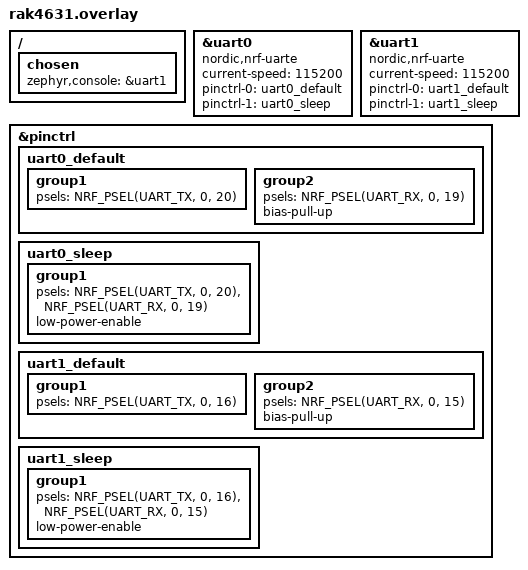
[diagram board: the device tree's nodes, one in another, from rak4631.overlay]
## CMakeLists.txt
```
cmake_minimum_required(VERSION 3.20.0)
find_package(Zephyr REQUIRED HINTS $ENV{ZEPHYR_BASE})
project(system_tower)
target_sources(app PRIVATE src/main.c)
```

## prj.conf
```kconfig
CONFIG_GPIO=y
CONFIG_SERIAL=y
CONFIG_CONSOLE=y
CONFIG_UART_CONSOLE=y
CONFIG_PRINTK=y
CONFIG_I2C=y

# LoRa (SX1262)
CONFIG_LORA=y
CONFIG_SPI=y

CONFIG_MAIN_STACK_SIZE=4096
CONFIG_SYSTEM_WORKQUEUE_STACK_SIZE=2048
```

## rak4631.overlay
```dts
/*
 * System Test - Tower
 * Console (debug): uart0 TX=P0.20, RX=P0.19 (115200) - RS485 경로
 * UART1: TX=P0.16, RX=P0.15 (115200) - debug/monitor 출력
 */

/ {
	chosen {
		zephyr,console = &uart1;
	};
};

&uart0 {
	compatible = "nordic,nrf-uarte";
	status = "okay";
	current-speed = <115200>;
	pinctrl-0 = <&uart0_default>;
	pinctrl-1 = <&uart0_sleep>;
	pinctrl-names = "default", "sleep";
};

&uart1 {
	compatible = "nordic,nrf-uarte";
	status = "okay";
	current-speed = <115200>;
	pinctrl-0 = <&uart1_default>;
	pinctrl-1 = <&uart1_sleep>;
	pinctrl-names = "default", "sleep";
};

&pinctrl {
	uart0_default: uart0_default {
		group1 {
			psels = <NRF_PSEL(UART_TX, 0, 20)>;
		};
		group2 {
			psels = <NRF_PSEL(UART_RX, 0, 19)>;
			bias-pull-up;
		};
	};

	uart0_sleep: uart0_sleep {
		group1 {
			psels = <NRF_PSEL(UART_TX, 0, 20)>,
				<NRF_PSEL(UART_RX, 0, 19)>;
			low-power-enable;
		};
	};

	uart1_default: uart1_default {
		group1 {
			psels = <NRF_PSEL(UART_TX, 0, 16)>;
		};
		group2 {
			psels = <NRF_PSEL(UART_RX, 0, 15)>;
			bias-pull-up;
		};
	};

	uart1_sleep: uart1_sleep {
		group1 {
			psels = <NRF_PSEL(UART_TX, 0, 16)>,
				<NRF_PSEL(UART_RX, 0, 15)>;
			low-power-enable;
		};
	};
};
```

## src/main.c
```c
/*
 * System Test - Tower (TX → RX loopback)
 *
 * 동작 (단일 스레드, 순차 처리):
 *   1. LoRa TX: 카운트 메시지 송신
 *   2. LoRa RX: Link에서 loopback된 메시지 수신 대기 (5초 timeout)
 *   3. 수신 결과를 uart1 (debug)과 RS485 (uart0)로 출력
 *   4. 반복
 *
 * RS485: MCP23017 → TMUX1574 MUX 활성화 후 uart0 사용
 * LoRa:  922.1 MHz, SF9, BW125, CR4/6
 */

#include <zephyr/kernel.h>
#include <zephyr/device.h>
#include <zephyr/drivers/gpio.h>
#include <zephyr/drivers/i2c.h>
#include <zephyr/drivers/uart.h>
#include <zephyr/drivers/lora.h>
#include <string.h>
#include <stdio.h>

#include "tower_port.h"

/* ── LoRa parameters ── */
#define LORA_FREQ       922100000
#define LORA_SF         12
#define LORA_BW         BW_125_KHZ
#define LORA_CR         CR_4_6
#define LORA_POWER      14
#define LORA_PREAMBLE   8
#define LORA_PAYLOAD    32

#define RX_TIMEOUT_MS   5000

/* ── Devices ── */
static const struct device *lora_dev;
static const struct device *gpio0_dev;
static const struct device *i2c_dev;
static const struct device *uart0_dev;  /* RS485 */
static uint8_t mcp_addr = 0;

/* ── MCP23017 helpers ── */
static int mcp_write(uint8_t reg, uint8_t val)
{
	uint8_t buf[2] = { reg, val };
	return i2c_write(i2c_dev, buf, 2, mcp_addr);
}

static int mcp_read(uint8_t reg, uint8_t *val)
{
	return i2c_write_read(i2c_dev, mcp_addr, &reg, 1, val, 1);
}

static int mux_enable_rs485(void)
{
	uint8_t iodira, gpa;

	if (mcp_read(MCP_REG_IODIRA, &iodira)) return -1;
	iodira &= ~(MCP_GPA3_MUX_SEL | MCP_GPA4_MUX_EN_N);
	if (mcp_write(MCP_REG_IODIRA, iodira)) return -1;

	if (mcp_read(MCP_REG_OLATA, &gpa)) return -1;
	gpa &= ~MCP_GPA3_MUX_SEL;   /* SEL=LOW → RS485 */
	gpa &= ~MCP_GPA4_MUX_EN_N;  /* EN#=LOW → Enable */
	return mcp_write(MCP_REG_OLATA, gpa);
}

/* ── RS485 direction control ── */
static void rs485_tx_mode(void)
{
	gpio_pin_set(gpio0_dev, PIN_RS485_RE_N, 1);  /* RE#=HIGH */
	gpio_pin_set(gpio0_dev, PIN_RS485_DE, 1);    /* DE=HIGH */
	k_usleep(100);
}

static void rs485_rx_mode(void)
{
	k_usleep(500);
	gpio_pin_set(gpio0_dev, PIN_RS485_DE, 0);    /* DE=LOW */
	gpio_pin_set(gpio0_dev, PIN_RS485_RE_N, 0);  /* RE#=LOW */
}

static void rs485_send(const char *str)
{
	rs485_tx_mode();
	while (*str) {
		uart_poll_out(uart0_dev, *str++);
	}
	rs485_rx_mode();
}

/* ── Dual output: printk (uart1) + RS485 (uart0) ── */
static void dual_print(const char *msg)
{
	printk("%s", msg);
	rs485_send(msg);
}

/* ── LoRa config ── */
static int lora_configure(bool tx)
{
	struct lora_modem_config config = {
		.frequency = LORA_FREQ,
		.bandwidth = LORA_BW,
		.datarate = LORA_SF,
		.coding_rate = LORA_CR,
		.preamble_len = LORA_PREAMBLE,
		.tx_power = LORA_POWER,
		.tx = tx,
		.iq_inverted = false,
		.public_network = false,
	};
	return lora_config(lora_dev, &config);
}

/* ── Main ── */
int main(void)
{
	char msg[128];

	/* GPIO init */
	gpio0_dev = DEVICE_DT_GET(DT_NODELABEL(gpio0));
	if (!device_is_ready(gpio0_dev)) {
		printk("GPIO0 not ready\n");
		return -1;
	}
	gpio_pin_configure(gpio0_dev, PIN_RS485_DE, GPIO_OUTPUT_LOW);
	gpio_pin_configure(gpio0_dev, PIN_RS485_RE_N, GPIO_OUTPUT_LOW);

	/* UART0 (RS485) */
	uart0_dev = DEVICE_DT_GET(DT_NODELABEL(uart0));
	if (!device_is_ready(uart0_dev)) {
		printk("UART0 not ready\n");
		return -1;
	}

	printk("\n========================================\n");
	printk("  System Test - Tower v1.0\n");
	printk("  LoRa TX -> Link -> Loopback -> RX\n");
	printk("========================================\n");

	/* I2C → MCP23017 → MUX enable */
	i2c_dev = DEVICE_DT_GET(DT_NODELABEL(i2c0));
	if (device_is_ready(i2c_dev)) {
		k_msleep(100);
		for (uint8_t addr = 0x20; addr <= 0x27; addr++) {
			uint8_t reg = MCP_REG_IODIRA, val;
			if (i2c_write_read(i2c_dev, addr, &reg, 1, &val, 1) == 0) {
				mcp_addr = addr;
				break;
			}
		}
		if (mcp_addr) {
			mux_enable_rs485();
			printk("[MUX] RS485 enabled (MCP@0x%02X)\n", mcp_addr);
		} else {
			printk("[MUX] MCP23017 not found\n");
		}
	}

	rs485_send("\r\n=== Tower System Test v1.0 ===\r\n");

	/* LoRa init */
	lora_dev = DEVICE_DT_GET(DT_ALIAS(lora0));
	if (!device_is_ready(lora_dev)) {
		dual_print("[LoRa] Device not ready!\r\n");
		return -1;
	}
	dual_print("[LoRa] SX1262 ready (922.1 MHz, SF9)\r\n");

	/* TX → RX loop (단일 스레드) */
	uint32_t count = 0;
	uint32_t rx_ok = 0, rx_fail = 0;

	while (1) {
		/* === TX === */
		if (lora_configure(true) < 0) {
			dual_print("[Tower-TX] Config failed\r\n");
			k_sleep(K_SECONDS(3));
			continue;
		}

		uint8_t payload[LORA_PAYLOAD];
		memset(payload, 0, LORA_PAYLOAD);
		int plen = snprintf((char *)payload, LORA_PAYLOAD,
				    "TOWER:%u", count);

		snprintf(msg, sizeof(msg),
			 "[Tower-TX] #%u \"%s\" sending...\r\n", count, payload);
		dual_print(msg);

		int ret = lora_send(lora_dev, payload, plen);
		if (ret < 0) {
			snprintf(msg, sizeof(msg),
				 "[Tower-TX] Send failed: %d\r\n", ret);
			dual_print(msg);
			k_sleep(K_SECONDS(3));
			continue;
		}

		snprintf(msg, sizeof(msg),
			 "[Tower-TX] Sent OK (%d bytes)\r\n", plen);
		dual_print(msg);
		count++;

		/* === RX (loopback 수신 대기) === */
		if (lora_configure(false) < 0) {
			dual_print("[Tower-RX] Config failed\r\n");
			k_sleep(K_SECONDS(3));
			continue;
		}

		uint8_t rx_buf[LORA_PAYLOAD];
		int16_t rssi;
		int8_t snr;

		ret = lora_recv(lora_dev, rx_buf, LORA_PAYLOAD,
				K_MSEC(RX_TIMEOUT_MS), &rssi, &snr);

		if (ret < 0) {
			rx_fail++;
			snprintf(msg, sizeof(msg),
				 "[Tower-RX] Timeout (no loopback) [ok=%u fail=%u]\r\n",
				 rx_ok, rx_fail);
			dual_print(msg);
		} else {
			rx_ok++;
			rx_buf[ret < LORA_PAYLOAD ? ret : LORA_PAYLOAD - 1] = '\0';
			snprintf(msg, sizeof(msg),
				 "[Tower-RX] Loopback OK! \"%s\" RSSI=%d SNR=%d [ok=%u fail=%u]\r\n",
				 rx_buf, rssi, snr, rx_ok, rx_fail);
			dual_print(msg);
		}

		/* 다음 TX까지 1초 대기 */
		k_sleep(K_SECONDS(1));
	}

	return 0;
}
```

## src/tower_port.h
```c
#ifndef TOWER_PORT_H
#define TOWER_PORT_H

/*
 * REVITA TOWER V1 - Port Assignment
 *
 * MCU: nRF52840 (RAK4631)
 * I/O Expander: MCP23017 (I2C 0x20)
 * UART MUX: TMUX1574PWR (4ch 2:1, SEL 1pin)
 */

/* ================================================================
 *  MCU Direct GPIO (nRF52840)
 * ================================================================ */

/* I2C Bus */
#define PIN_I2C_SDA             13      /* P0.13 */
#define PIN_I2C_SCL             14      /* P0.14 */

/* UART0 - RS485 (via TMUX1574 MUX) */
#define PIN_UART0_RX            19      /* P0.19  RAK_UART1_RX → MUX COM_RX */
#define PIN_UART0_TX            20      /* P0.20  RAK_UART1_TX → MUX COM_TX */

/* UART1 - Debug */
#define PIN_UART1_RX            15      /* P0.15  RAK_UART2_RX */
#define PIN_UART1_TX            16      /* P0.16  RAK_UART2_TX */

/* RS485 Direction Control */
#define PIN_RS485_DE            17      /* P0.17  DE:  HIGH=TX enable */
#define PIN_RS485_RE_N          21      /* P0.21  RE#: LOW=RX enable */

/* SPI (RAK4631 LoRa - SX1262) */
#define PIN_SPI_CLK             3       /* P0.03 */
#define PIN_SPI_CS              26      /* P0.26 */
#define PIN_SPI_MISO            29      /* P0.29 */
#define PIN_SPI_MOSI            30      /* P0.30 */

/* ADC */
#define PIN_BATT_ADC            5       /* P0.05  배터리 전압 확인 (AIN0) */
#define PIN_AIN1                31      /* P0.31 */

/* LED */
#define PIN_LED1                35      /* P1.03  Green */

/* Sensor */
#define PIN_VIB_SENSOR          36      /* P1.04  진동 센서 Digital Input */

/* Button */
#define PIN_BUTTON              34      /* P1.02  버튼 입력 */

/* USB (미확인 - 검토사항 참조) */
/* MCU_USB_D_N  - 핀 미확인 */
/* MCU_USB_D_P  - 핀 미확인 */

/* LTE 제어 (미확인 - 검토사항 참조) */
/* LTE_PW_ON   - 핀 미확인 */
/* LTE_DTR     - 핀 미확인 */
/* LTE_RI      - 핀 미확인 */

/* 기타 미확인 */
/* P0.26 UARPC2  - 용도 미확인 (SPI_CS와 공유?) */
/* P1.01 SIO_35  - 용도 미확인 */

/* ================================================================
 *  MCP23017 I2C I/O Expander (0x20)
 * ================================================================ */

/* MCP23017 Registers */
#define MCP_REG_IODIRA          0x00
#define MCP_REG_IODIRB          0x01
#define MCP_REG_OLATA           0x14
#define MCP_REG_OLATB           0x15

/* GPA Port */
#define MCP_GPA0_LTE_RST_N     (1 << 0)    /* LTE 모듈 리셋 (Active Low) */
#define MCP_GPA1                (1 << 1)    /* 공란 - 미할당 */
#define MCP_GPA2_12V_EN         (1 << 2)    /* 12V 전원 활성화 */
#define MCP_GPA3_MUX_SEL        (1 << 3)    /* TMUX1574 SEL: LOW=RS485, HIGH=SBC */
#define MCP_GPA4_MUX_EN_N       (1 << 4)    /* TMUX1574 EN#: LOW=Enable */
#define MCP_GPA5_3V3_EN         (1 << 5)    /* 3.3V 전원 활성화 */
#define MCP_GPA6_5V_EN          (1 << 6)    /* 5V 전원 활성화 */
#define MCP_GPA7_CAM_EN         (1 << 7)    /* 카메라 활성화 */

/* GPB Port */
#define MCP_GPB0_SBC_RST_N      (1 << 0)    /* SBC 리셋 (Active Low) */
#define MCP_GPB1_BUZZER_EN      (1 << 1)    /* 부저 활성화 */
#define MCP_GPB2                (1 << 2)    /* 공란 - 미할당 */
#define MCP_GPB3                (1 << 3)    /* 공란 - 미할당 */
#define MCP_GPB4                (1 << 4)    /* 공란 - 미할당 */
#define MCP_GPB5                (1 << 5)    /* 공란 - 미할당 */
#define MCP_GPB6_LED_EN         (1 << 6)    /* LED 활성화 */
#define MCP_GPB7                (1 << 7)    /* 공란 - 미할당 */

#endif /* TOWER_PORT_H */
```
